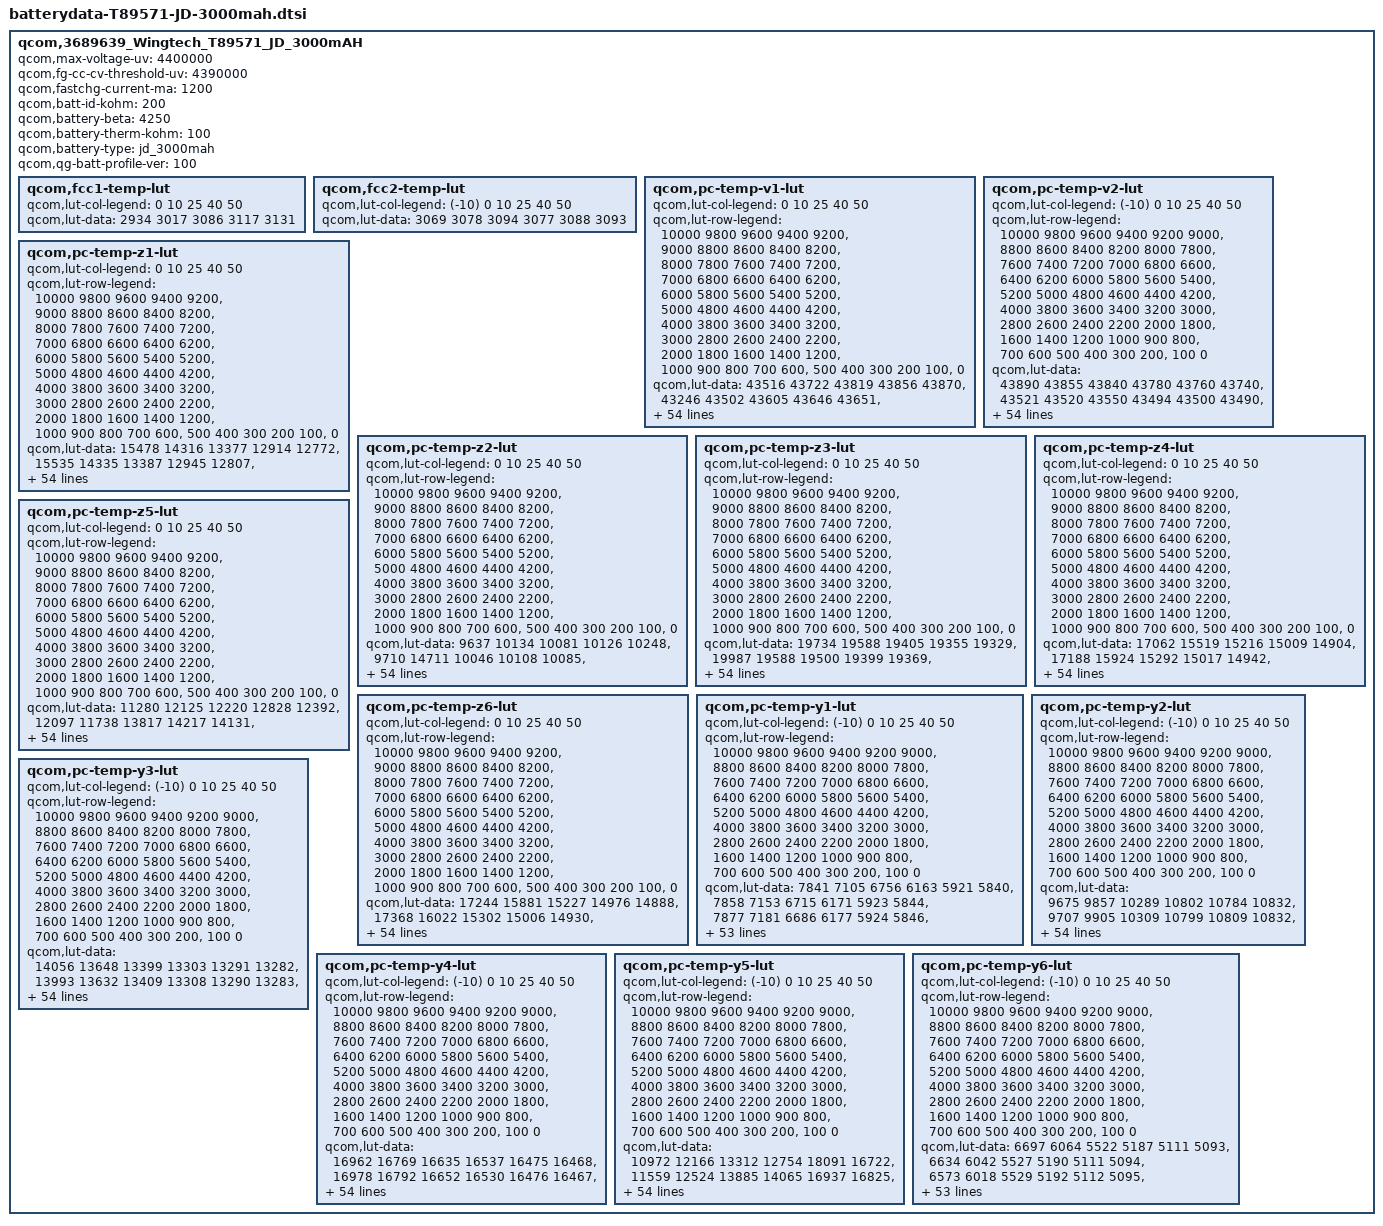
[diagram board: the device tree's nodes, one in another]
qcom,3689639_Wingtech_T89571_JD_3000mAH {
    /* 3689639_Wingtech_T89571_JD_3000mAH_averaged_MasterSlave_27thNov2018 */
    qcom,max-voltage-uv = <4400000>;
    qcom,fg-cc-cv-threshold-uv = <4390000>;
    qcom,fastchg-current-ma = <1200>; /* charging current is at 1A. */
    qcom,batt-id-kohm = <200>;
    qcom,battery-beta = <4250>;
    qcom,battery-therm-kohm = <100>;
    qcom,battery-type = "jd_3000mah";
    qcom,qg-batt-profile-ver = <100>;

	qcom,fcc1-temp-lut {
		qcom,lut-col-legend = <0 10 25 40 50>;
		qcom,lut-data = <2934 3017 3086 3117 3131>;
	};

	qcom,fcc2-temp-lut {
		qcom,lut-col-legend = <(-10) 0 10 25 40 50>;
		qcom,lut-data = <3069 3078 3094 3077 3088 3093>;
	};

	qcom,pc-temp-v1-lut {
		qcom,lut-col-legend = <0 10 25 40 50>;
		qcom,lut-row-legend = <10000 9800 9600 9400 9200>,
			<9000 8800 8600 8400 8200>,
			<8000 7800 7600 7400 7200>,
			<7000 6800 6600 6400 6200>,
			<6000 5800 5600 5400 5200>,
			<5000 4800 4600 4400 4200>,
			<4000 3800 3600 3400 3200>,
			<3000 2800 2600 2400 2200>,
			<2000 1800 1600 1400 1200>,
			<1000 900 800 700 600>,
			<500 400 300 200 100>,
			<0>;
		qcom,lut-data = <43516 43722 43819 43856 43870>,
			<43246 43502 43605 43646 43651>,
			<42996 43238 43377 43431 43442>,
			<42763 42981 43146 43205 43220>,
			<42538 42745 42913 42975 42992>,
			<42317 42515 42674 42743 42762>,
			<42101 42287 42435 42510 42531>,
			<41890 42064 42200 42277 42299>,
			<41683 41847 41971 42045 42069>,
			<41484 41635 41747 41817 41839>,
			<41302 41432 41527 41592 41613>,
			<41129 41250 41317 41372 41391>,
			<40929 41079 41129 41155 41173>,
			<40680 40877 40952 40945 40960>,
			<40428 40608 40741 40737 40751>,
			<40201 40341 40482 40532 40552>,
			<39986 40137 40250 40334 40359>,
			<39817 39963 40081 40154 40175>,
			<39693 39814 39933 39987 40000>,
			<39584 39693 39782 39821 39827>,
			<39465 39573 39634 39659 39664>,
			<39346 39431 39459 39484 39492>,
			<39228 39276 39201 39242 39272>,
			<39111 39108 38942 38971 39015>,
			<38998 38915 38781 38802 38833>,
			<38887 38739 38662 38698 38717>,
			<38776 38611 38567 38606 38617>,
			<38673 38506 38491 38511 38514>,
			<38582 38428 38423 38421 38417>,
			<38499 38367 38354 38334 38326>,
			<38431 38319 38290 38252 38242>,
			<38375 38278 38231 38180 38167>,
			<38325 38242 38177 38118 38101>,
			<38277 38208 38126 38061 38040>,
			<38234 38177 38080 38008 37982>,
			<38194 38143 38037 37959 37926>,
			<38161 38108 37995 37908 37866>,
			<38124 38069 37956 37859 37802>,
			<38072 38013 37903 37799 37729>,
			<38001 37925 37814 37712 37642>,
			<37913 37818 37703 37605 37541>,
			<37791 37698 37586 37489 37425>,
			<37652 37560 37452 37358 37290>,
			<37497 37401 37296 37204 37137>,
			<37348 37259 37153 37063 36997>,
			<37240 37172 37069 36977 36917>,
			<37202 37143 37042 36956 36896>,
			<37172 37117 37030 36940 36881>,
			<37145 37093 37012 36921 36862>,
			<37094 37048 36959 36862 36789>,
			<36881 36818 36702 36605 36511>,
			<36442 36384 36266 36171 36068>,
			<35873 35813 35697 35603 35496>,
			<35103 35036 34916 34831 34715>,
			<33880 33825 33701 33646 33512>,
			<30000 30000 30000 30000 30000>;
	};

	qcom,pc-temp-v2-lut {
		qcom,lut-col-legend = <(-10) 0 10 25 40 50>;
		qcom,lut-row-legend = <10000 9800 9600 9400 9200 9000>,
			<8800 8600 8400 8200 8000 7800>,
			<7600 7400 7200 7000 6800 6600>,
			<6400 6200 6000 5800 5600 5400>,
			<5200 5000 4800 4600 4400 4200>,
			<4000 3800 3600 3400 3200 3000>,
			<2800 2600 2400 2200 2000 1800>,
			<1600 1400 1200 1000 900 800>,
			<700 600 500 400 300 200>,
			<100 0>;
		qcom,lut-data = <43890 43855 43840 43780 43760 43740>,
			<43521 43520 43550 43494 43500 43490>,
			<43183 43209 43276 43224 43248 43247>,
			<42881 42926 43016 42973 43006 43010>,
			<42611 42668 42771 42738 42774 42780>,
			<42356 42420 42530 42507 42543 42550>,
			<42113 42178 42289 42275 42313 42319>,
			<41878 41947 42053 42046 42085 42089>,
			<41640 41740 41828 41820 41858 41862>,
			<41402 41549 41611 41597 41634 41637>,
			<41192 41351 41397 41378 41412 41415>,
			<41027 41139 41182 41159 41195 41197>,
			<40853 40930 40981 40950 40982 40982>,
			<40595 40750 40820 40765 40779 40776>,
			<40273 40579 40669 40593 40581 40575>,
			<39980 40332 40440 40395 40385 40381>,
			<39693 39925 40077 40155 40189 40192>,
			<39448 39579 39763 39935 40004 40011>,
			<39286 39414 39576 39781 39842 39844>,
			<39153 39289 39420 39643 39682 39676>,
			<39012 39141 39249 39452 39482 39475>,
			<38861 38975 39073 39192 39234 39239>,
			<38714 38818 38910 38964 39015 39027>,
			<38576 38678 38760 38796 38833 38844>,
			<38448 38546 38622 38653 38677 38684>,
			<38335 38416 38500 38529 38550 38554>,
			<38234 38289 38389 38420 38443 38444>,
			<38145 38184 38283 38319 38344 38343>,
			<38071 38098 38179 38224 38253 38250>,
			<38005 38024 38085 38136 38167 38165>,
			<37943 37963 38002 38059 38090 38086>,
			<37886 37909 37927 37989 38017 38012>,
			<37830 37861 37869 37925 37944 37944>,
			<37773 37817 37821 37866 37873 37883>,
			<37718 37773 37777 37809 37799 37813>,
			<37662 37729 37739 37747 37724 37714>,
			<37606 37682 37699 37681 37648 37603>,
			<37550 37628 37647 37617 37564 37502>,
			<37492 37564 37583 37554 37473 37406>,
			<37434 37491 37511 37485 37384 37316>,
			<37374 37406 37431 37400 37303 37237>,
			<37311 37313 37336 37299 37211 37145>,
			<37243 37221 37219 37176 37092 37025>,
			<37165 37127 37100 37045 36962 36896>,
			<37072 37032 36984 36922 36848 36786>,
			<36958 36942 36902 36871 36810 36757>,
			<36898 36900 36874 36853 36798 36746>,
			<36819 36858 36846 36836 36780 36725>,
			<36721 36792 36798 36805 36751 36690>,
			<36563 36678 36697 36714 36645 36562>,
			<36288 36423 36445 36421 36315 36196>,
			<35863 35970 35968 35926 35826 35689>,
			<35242 35328 35318 35294 35180 35033>,
			<34331 34415 34409 34447 34306 34145>,
			<32892 33070 33002 33139 33077 32828>,
			<28907 28291 28121 27780 28879 28426>;
	};

	qcom,pc-temp-z1-lut {
		qcom,lut-col-legend = <0 10 25 40 50>;
		qcom,lut-row-legend = <10000 9800 9600 9400 9200>,
			<9000 8800 8600 8400 8200>,
			<8000 7800 7600 7400 7200>,
			<7000 6800 6600 6400 6200>,
			<6000 5800 5600 5400 5200>,
			<5000 4800 4600 4400 4200>,
			<4000 3800 3600 3400 3200>,
			<3000 2800 2600 2400 2200>,
			<2000 1800 1600 1400 1200>,
			<1000 900 800 700 600>,
			<500 400 300 200 100>,
			<0>;
		qcom,lut-data = <15478 14316 13377 12914 12772>,
			<15535 14335 13387 12945 12807>,
			<15545 14317 13391 12941 12805>,
			<15528 14309 13388 12935 12804>,
			<15511 14329 13383 12925 12800>,
			<15504 14349 13375 12920 12797>,
			<15500 14341 13364 12916 12796>,
			<15498 14311 13354 12914 12797>,
			<15495 14298 13341 12914 12799>,
			<15492 14305 13338 12915 12802>,
			<15486 14312 13346 12915 12803>,
			<15475 14315 13356 12916 12804>,
			<15458 14322 13358 12918 12806>,
			<15425 14319 13358 12921 12808>,
			<15388 14272 13353 12923 12810>,
			<15362 14228 13335 12921 12813>,
			<15339 14224 13325 12920 12816>,
			<15320 14229 13331 12921 12819>,
			<15306 14237 13344 12927 12822>,
			<15296 14254 13354 12932 12824>,
			<15285 14266 13363 12937 12826>,
			<15261 14266 13370 12942 12829>,
			<15246 14268 13376 12944 12832>,
			<15243 14275 13382 12946 12836>,
			<15241 14286 13389 12949 12840>,
			<15245 14296 13397 12953 12844>,
			<15265 14298 13401 12958 12848>,
			<15288 14297 13402 12964 12854>,
			<15310 14303 13404 12970 12860>,
			<15329 14317 13409 12977 12866>,
			<15332 14328 13417 12984 12872>,
			<15298 14327 13425 12990 12877>,
			<15270 14323 13436 12994 12882>,
			<15295 14325 13443 12998 12887>,
			<15347 14335 13446 13003 12892>,
			<15367 14347 13450 13009 12897>,
			<15352 14357 13458 13015 12900>,
			<15338 14367 13473 13021 12903>,
			<15364 14381 13484 13027 12905>,
			<15419 14404 13487 13032 12909>,
			<15441 14419 13490 13037 12914>,
			<15425 14415 13494 13041 12918>,
			<15408 14409 13499 13045 12922>,
			<15381 14415 13508 13049 12923>,
			<15378 14420 13530 13056 12926>,
			<15465 14450 13544 13063 12934>,
			<15436 14428 13522 13066 12935>,
			<15402 14439 13520 13067 12935>,
			<15359 14429 13533 13066 12939>,
			<15443 14438 13542 13070 12943>,
			<15400 14448 13541 13085 12950>,
			<15417 14459 13563 13089 12958>,
			<15462 14512 13586 13104 12971>,
			<15500 14565 13613 13127 12990>,
			<15500 14565 13613 13127 12990>,
			<15500 14565 13613 13127 12990>;
	};

	qcom,pc-temp-z2-lut {
		qcom,lut-col-legend = <0 10 25 40 50>;
		qcom,lut-row-legend = <10000 9800 9600 9400 9200>,
			<9000 8800 8600 8400 8200>,
			<8000 7800 7600 7400 7200>,
			<7000 6800 6600 6400 6200>,
			<6000 5800 5600 5400 5200>,
			<5000 4800 4600 4400 4200>,
			<4000 3800 3600 3400 3200>,
			<3000 2800 2600 2400 2200>,
			<2000 1800 1600 1400 1200>,
			<1000 900 800 700 600>,
			<500 400 300 200 100>,
			<0>;
		qcom,lut-data = <9637 10134 10081 10126 10248>,
			<9710 14711 10046 10108 10085>,
			<9742 11438 10101 10220 10135>,
			<9759 9866 10314 10230 10216>,
			<9765 9852 10442 10233 10245>,
			<9757 9844 10270 10220 10240>,
			<9744 9834 10033 10178 10187>,
			<9737 9824 9986 10143 10147>,
			<9733 9816 9972 10117 10139>,
			<9729 9810 9971 10097 10134>,
			<9722 9805 10059 10081 10125>,
			<9714 9802 10151 10069 10099>,
			<9704 9798 10218 10074 10083>,
			<9686 9793 10334 10106 10056>,
			<9668 9787 10390 10134 10041>,
			<9659 9782 10480 10151 10058>,
			<9652 9786 10540 10163 10084>,
			<9649 9798 10363 10144 10105>,
			<9649 9810 10091 10080 10121>,
			<9652 9827 10048 10056 10133>,
			<9657 9841 10059 10088 10142>,
			<9664 9847 10068 10123 10149>,
			<9669 9853 10068 10138 10147>,
			<9673 9861 10063 10155 10131>,
			<9677 9877 10060 10148 10129>,
			<9681 9887 10056 10103 10160>,
			<9684 9888 10058 10083 10193>,
			<9687 9890 10067 10130 10211>,
			<9695 9892 10075 10194 10224>,
			<9705 9896 10083 10214 10215>,
			<9712 9900 10095 10213 10156>,
			<9719 9902 10097 10206 10115>,
			<9726 9904 10095 10191 10086>,
			<9734 9907 10093 10178 10063>,
			<9744 9914 10095 10183 10072>,
			<9748 9921 10100 10200 10105>,
			<9729 9929 10106 10219 10152>,
			<9708 9938 10114 10240 10238>,
			<9685 9948 10124 10262 10292>,
			<9630 9959 10139 10293 10287>,
			<9611 9969 10154 10320 10277>,
			<9616 9977 10163 10322 10263>,
			<9618 9986 10170 10317 10237>,
			<9513 10000 10174 10293 10273>,
			<9545 10094 10201 10260 10316>,
			<9535 10045 10257 10255 10264>,
			<9544 10099 10243 10256 10285>,
			<9504 10108 10254 10252 10268>,
			<9494 10127 10371 10271 10315>,
			<9536 9993 10348 10375 10348>,
			<9487 9960 10329 10342 10218>,
			<9438 10007 10310 10271 10108>,
			<9435 9849 10372 10192 10030>,
			<9334 9852 10319 10130 9988>,
			<9334 9852 10319 10130 9988>,
			<9334 9852 10319 10130 9988>;
	};

	qcom,pc-temp-z3-lut {
		qcom,lut-col-legend = <0 10 25 40 50>;
		qcom,lut-row-legend = <10000 9800 9600 9400 9200>,
			<9000 8800 8600 8400 8200>,
			<8000 7800 7600 7400 7200>,
			<7000 6800 6600 6400 6200>,
			<6000 5800 5600 5400 5200>,
			<5000 4800 4600 4400 4200>,
			<4000 3800 3600 3400 3200>,
			<3000 2800 2600 2400 2200>,
			<2000 1800 1600 1400 1200>,
			<1000 900 800 700 600>,
			<500 400 300 200 100>,
			<0>;
		qcom,lut-data = <19734 19588 19405 19355 19329>,
			<19987 19588 19500 19399 19369>,
			<20050 19744 19553 19447 19398>,
			<20054 19814 19577 19466 19430>,
			<20047 19824 19589 19475 19447>,
			<20031 19829 19594 19478 19450>,
			<20013 19827 19596 19480 19450>,
			<20008 19819 19593 19480 19450>,
			<20012 19808 19589 19477 19447>,
			<20014 19793 19585 19472 19442>,
			<20008 19778 19589 19458 19434>,
			<19996 19765 19595 19438 19420>,
			<19995 19753 19597 19431 19411>,
			<20040 19750 19596 19429 19405>,
			<20085 19766 19593 19429 19399>,
			<20085 19781 19588 19427 19391>,
			<20075 19771 19580 19424 19381>,
			<20062 19741 19548 19416 19377>,
			<20027 19711 19506 19401 19374>,
			<19985 19676 19496 19395 19372>,
			<19960 19653 19494 19397 19370>,
			<19942 19664 19494 19401 19369>,
			<19933 19697 19512 19407 19369>,
			<19933 19722 19533 19416 19370>,
			<19938 19742 19532 19415 19368>,
			<19946 19754 19524 19396 19356>,
			<19968 19753 19517 19384 19348>,
			<19985 19751 19510 19389 19361>,
			<19989 19747 19505 19398 19387>,
			<19988 19740 19508 19412 19399>,
			<19980 19730 19513 19437 19409>,
			<19961 19719 19518 19447 19411>,
			<19940 19707 19523 19442 19405>,
			<19924 19695 19526 19434 19395>,
			<19908 19684 19524 19426 19386>,
			<19876 19673 19520 19418 19376>,
			<19758 19662 19515 19412 19374>,
			<19639 19651 19508 19408 19376>,
			<19575 19647 19501 19405 19377>,
			<19484 19647 19496 19404 19375>,
			<19449 19646 19492 19403 19371>,
			<19451 19640 19489 19401 19370>,
			<19449 19630 19486 19396 19371>,
			<19384 19616 19482 19392 19372>,
			<19349 19572 19471 19386 19372>,
			<19326 19389 19445 19375 19356>,
			<19323 19347 19442 19369 19350>,
			<19323 19332 19397 19366 19347>,
			<19320 19324 19359 19364 19335>,
			<19317 19299 19377 19349 19338>,
			<19321 19312 19388 19359 19359>,
			<19332 19308 19397 19361 19372>,
			<19342 19311 19358 19375 19374>,
			<19353 19348 19343 19370 19379>,
			<19353 19348 19343 19370 19379>,
			<19353 19348 19343 19370 19379>;
	};

	qcom,pc-temp-z4-lut {
		qcom,lut-col-legend = <0 10 25 40 50>;
		qcom,lut-row-legend = <10000 9800 9600 9400 9200>,
			<9000 8800 8600 8400 8200>,
			<8000 7800 7600 7400 7200>,
			<7000 6800 6600 6400 6200>,
			<6000 5800 5600 5400 5200>,
			<5000 4800 4600 4400 4200>,
			<4000 3800 3600 3400 3200>,
			<3000 2800 2600 2400 2200>,
			<2000 1800 1600 1400 1200>,
			<1000 900 800 700 600>,
			<500 400 300 200 100>,
			<0>;
		qcom,lut-data = <17062 15519 15216 15009 14904>,
			<17188 15924 15292 15017 14942>,
			<17137 15875 15406 15105 14987>,
			<16824 15809 15260 15064 14989>,
			<16495 15651 15135 14997 14940>,
			<16279 15466 15069 14951 14903>,
			<16091 15348 15016 14913 14873>,
			<15933 15255 14969 14879 14846>,
			<15796 15184 14926 14845 14816>,
			<15680 15132 14883 14819 14791>,
			<15584 15086 14831 14809 14781>,
			<15501 15037 14783 14802 14775>,
			<15427 14989 14745 14791 14769>,
			<15355 14948 14707 14774 14760>,
			<15293 14910 14699 14757 14750>,
			<15250 14882 14702 14745 14742>,
			<15216 14871 14707 14735 14735>,
			<15184 14864 14722 14728 14726>,
			<15151 14863 14740 14723 14714>,
			<15123 14858 14742 14721 14708>,
			<15101 14850 14737 14721 14711>,
			<15081 14831 14735 14722 14717>,
			<15059 14799 14812 14781 14766>,
			<15031 14793 14909 14902 14881>,
			<15002 14834 14932 14931 14919>,
			<14977 14876 14939 14927 14916>,
			<14953 14891 14934 14921 14908>,
			<14935 14903 14913 14898 14877>,
			<14923 14900 14884 14860 14824>,
			<14913 14884 14856 14820 14786>,
			<14909 14865 14825 14771 14753>,
			<14906 14849 14798 14743 14734>,
			<14902 14832 14773 14729 14722>,
			<14895 14818 14756 14721 14715>,
			<14887 14804 14747 14722 14716>,
			<14892 14793 14741 14725 14721>,
			<14996 14784 14738 14728 14726>,
			<15098 14776 14737 14732 14733>,
			<15137 14770 14737 14736 14739>,
			<15212 14764 14748 14745 14745>,
			<15235 14761 14761 14755 14750>,
			<15213 14758 14756 14753 14749>,
			<15196 14757 14745 14746 14740>,
			<15223 14756 14743 14748 14740>,
			<15139 14755 14734 14747 14739>,
			<15103 14887 14701 14711 14708>,
			<15100 14921 14689 14699 14696>,
			<15094 14929 14722 14676 14672>,
			<15088 14930 14749 14657 14659>,
			<15079 14947 14726 14675 14661>,
			<15076 14947 14746 14705 14680>,
			<15098 14969 14750 14715 14678>,
			<15110 14980 14798 14703 14680>,
			<15122 14964 14825 14712 14677>,
			<15122 14964 14825 14712 14677>,
			<15122 14964 14825 14712 14677>;
	};

	qcom,pc-temp-z5-lut {
		qcom,lut-col-legend = <0 10 25 40 50>;
		qcom,lut-row-legend = <10000 9800 9600 9400 9200>,
			<9000 8800 8600 8400 8200>,
			<8000 7800 7600 7400 7200>,
			<7000 6800 6600 6400 6200>,
			<6000 5800 5600 5400 5200>,
			<5000 4800 4600 4400 4200>,
			<4000 3800 3600 3400 3200>,
			<3000 2800 2600 2400 2200>,
			<2000 1800 1600 1400 1200>,
			<1000 900 800 700 600>,
			<500 400 300 200 100>,
			<0>;
		qcom,lut-data = <11280 12125 12220 12828 12392>,
			<12097 11738 13817 14217 14131>,
			<12535 12771 14025 14939 14837>,
			<12797 13464 14273 15237 15688>,
			<12992 13758 14487 15575 16407>,
			<13144 13972 14908 15816 16687>,
			<13282 14177 15480 16012 16765>,
			<13450 14387 15868 16261 16883>,
			<13699 14502 16196 16685 17372>,
			<13878 14540 16708 16972 17880>,
			<13914 14571 18543 16706 17799>,
			<13932 14678 20418 16156 17317>,
			<14024 14968 22184 16122 17074>,
			<14720 15496 24684 16815 17262>,
			<15487 17415 25191 17632 17446>,
			<15792 19103 25545 18506 17343>,
			<15990 18843 25481 19213 17227>,
			<16000 17850 23019 19105 17364>,
			<15585 17107 19799 18560 18208>,
			<15089 16431 19438 18423 19036>,
			<14979 15997 20472 19858 19630>,
			<15044 17644 22332 21583 20118>,
			<15214 22545 30088 23072 20284>,
			<15636 27672 37846 24815 19892>,
			<16329 34651 36414 24185 18907>,
			<17506 39339 29997 19522 16177>,
			<20218 38643 25349 16266 14326>,
			<22266 36416 22177 15738 14633>,
			<23134 34270 20469 15578 15443>,
			<23970 32104 20532 16507 16482>,
			<24001 29999 20881 19643 18472>,
			<22926 28069 21629 22471 20246>,
			<21682 26292 24109 24821 21735>,
			<21022 25087 26888 26542 22798>,
			<20484 24220 29570 27324 23020>,
			<19475 23586 31797 27837 23060>,
			<16672 23036 31883 27820 23232>,
			<14041 22562 30752 26849 23794>,
			<12942 22753 29478 25551 24175>,
			<11678 24891 27868 23954 22595>,
			<11236 26501 26387 22231 20001>,
			<11298 25608 25801 21165 19384>,
			<11349 24385 25334 20374 19331>,
			<11161 23561 24286 19302 19073>,
			<11267 21185 24114 18761 18634>,
			<11167 12582 23130 19152 18085>,
			<11134 11765 22773 18567 17722>,
			<11119 11547 16052 19407 19027>,
			<11088 11456 13395 21028 19149>,
			<11102 11276 14531 17433 18677>,
			<11189 11526 14760 15411 17254>,
			<11232 11406 14655 14587 17796>,
			<11235 11341 12687 15364 17242>,
			<11182 11472 12097 14511 17144>,
			<11182 11472 12097 14511 17144>,
			<11182 11472 12097 14511 17144>;
	};

	qcom,pc-temp-z6-lut {
		qcom,lut-col-legend = <0 10 25 40 50>;
		qcom,lut-row-legend = <10000 9800 9600 9400 9200>,
			<9000 8800 8600 8400 8200>,
			<8000 7800 7600 7400 7200>,
			<7000 6800 6600 6400 6200>,
			<6000 5800 5600 5400 5200>,
			<5000 4800 4600 4400 4200>,
			<4000 3800 3600 3400 3200>,
			<3000 2800 2600 2400 2200>,
			<2000 1800 1600 1400 1200>,
			<1000 900 800 700 600>,
			<500 400 300 200 100>,
			<0>;
		qcom,lut-data = <17244 15881 15227 14976 14888>,
			<17368 16022 15302 15006 14930>,
			<17347 16037 15368 15067 14966>,
			<17170 16036 15315 15055 14977>,
			<16980 15960 15265 15034 14968>,
			<16849 15852 15233 15017 14959>,
			<16734 15782 15206 15001 14947>,
			<16642 15725 15181 14985 14934>,
			<16566 15677 15157 14969 14921>,
			<16501 15639 15135 14955 14908>,
			<16441 15606 15116 14942 14898>,
			<16387 15571 15098 14929 14889>,
			<16344 15537 15082 14919 14880>,
			<16310 15510 15067 14912 14873>,
			<16279 15489 15059 14904 14865>,
			<16247 15472 15054 14898 14858>,
			<16215 15456 15049 14891 14850>,
			<16182 15441 15037 14883 14844>,
			<16144 15428 15026 14874 14837>,
			<16107 15411 15023 14870 14834>,
			<16080 15401 15022 14872 14834>,
			<16058 15403 15023 14874 14836>,
			<16042 15411 15067 14904 14857>,
			<16028 15423 15120 14962 14908>,
			<16018 15452 15130 14974 14925>,
			<16018 15479 15131 14966 14920>,
			<16025 15488 15128 14956 14913>,
			<16031 15495 15117 14948 14906>,
			<16031 15494 15105 14939 14899>,
			<16030 15485 15095 14932 14891>,
			<16028 15474 15087 14926 14884>,
			<16020 15465 15080 14919 14876>,
			<16011 15455 15075 14911 14868>,
			<16004 15447 15070 14905 14861>,
			<15998 15439 15067 14901 14857>,
			<15989 15432 15064 14899 14854>,
			<15978 15428 15062 14898 14854>,
			<15967 15424 15060 14898 14858>,
			<15961 15424 15060 14898 14861>,
			<15956 15427 15065 14901 14863>,
			<15952 15431 15070 14906 14864>,
			<15952 15432 15070 14905 14864>,
			<15951 15433 15067 14901 14861>,
			<15943 15433 15067 14901 14862>,
			<15899 15415 15062 14899 14862>,
			<15876 15389 15038 14878 14841>,
			<15873 15383 15033 14870 14833>,
			<15873 15380 15023 14859 14821>,
			<15871 15379 15018 14850 14809>,
			<15875 15381 15021 14852 14812>,
			<15888 15395 15039 14871 14833>,
			<15915 15414 15050 14879 14842>,
			<15945 15436 15059 14885 14847>,
			<15987 15468 15072 14892 14852>,
			<15987 15468 15072 14892 14852>,
			<15987 15468 15072 14892 14852>;
	};

	qcom,pc-temp-y1-lut {
		qcom,lut-col-legend = <(-10) 0 10 25 40 50>;
		qcom,lut-row-legend = <10000 9800 9600 9400 9200 9000>,
			<8800 8600 8400 8200 8000 7800>,
			<7600 7400 7200 7000 6800 6600>,
			<6400 6200 6000 5800 5600 5400>,
			<5200 5000 4800 4600 4400 4200>,
			<4000 3800 3600 3400 3200 3000>,
			<2800 2600 2400 2200 2000 1800>,
			<1600 1400 1200 1000 900 800>,
			<700 600 500 400 300 200>,
			<100 0>;
		qcom,lut-data = <7841 7105 6756 6163 5921 5840>,
			<7858 7153 6715 6171 5923 5844>,
			<7877 7181 6686 6177 5924 5846>,
			<7894 7194 6668 6180 5924 5846>,
			<7906 7198 6658 6182 5924 5846>,
			<7910 7198 6656 6182 5923 5845>,
			<7907 7182 6669 6179 5921 5842>,
			<7901 7163 6683 6174 5918 5838>,
			<7896 7158 6677 6173 5917 5838>,
			<7885 7151 6656 6173 5917 5838>,
			<7883 7149 6647 6173 5917 5839>,
			<7898 7164 6648 6170 5916 5838>,
			<7910 7181 6649 6167 5916 5838>,
			<7898 7188 6648 6167 5915 5837>,
			<7876 7193 6647 6168 5914 5837>,
			<7871 7198 6651 6172 5914 5837>,
			<7882 7206 6674 6184 5915 5838>,
			<7894 7211 6690 6194 5917 5840>,
			<7902 7206 6686 6195 5918 5841>,
			<7910 7196 6680 6195 5918 5842>,
			<7907 7196 6676 6195 5919 5843>,
			<7892 7207 6673 6195 5921 5844>,
			<7885 7214 6672 6195 5923 5846>,
			<7890 7217 6669 6196 5925 5849>,
			<7896 7220 6666 6197 5927 5851>,
			<7893 7212 6668 6201 5930 5854>,
			<7880 7192 6673 6209 5934 5855>,
			<7871 7184 6677 6213 5938 5857>,
			<7871 7195 6682 6212 5941 5860>,
			<7872 7205 6685 6211 5944 5863>,
			<7880 7198 6681 6213 5947 5867>,
			<7895 7178 6674 6218 5951 5871>,
			<7895 7172 6673 6221 5955 5874>,
			<7885 7175 6674 6223 5960 5877>,
			<7876 7179 6676 6224 5965 5879>,
			<7862 7188 6682 6227 5968 5882>,
			<7842 7201 6691 6231 5970 5884>,
			<7828 7201 6696 6234 5972 5887>,
			<7820 7177 6699 6239 5973 5889>,
			<7823 7161 6700 6244 5975 5890>,
			<7881 7173 6688 6249 5977 5892>,
			<7934 7188 6682 6254 5979 5894>,
			<7869 7220 6689 6258 5982 5897>,
			<7866 7223 6713 6262 5987 5902>,
			<7977 7252 6732 6279 5993 5906>,
			<7923 7249 6742 6275 5999 5910>,
			<7944 7246 6752 6279 6005 5911>,
			<7951 7245 6726 6285 6002 5911>,
			<7958 7264 6741 6294 6003 5914>,
			<7977 7276 6725 6295 6002 5913>,
			<7990 7288 6736 6290 6004 5916>,
			<8021 7287 6754 6311 6015 5924>,
			<8046 7299 6760 6338 6028 5932>,
			<8189 7348 6799 6346 6048 5946>,
			<8189 7348 6799 6346 6048 5946>,
			<8189 7348 6799 6346 6048 5946>;
	};

	qcom,pc-temp-y2-lut {
		qcom,lut-col-legend = <(-10) 0 10 25 40 50>;
		qcom,lut-row-legend = <10000 9800 9600 9400 9200 9000>,
			<8800 8600 8400 8200 8000 7800>,
			<7600 7400 7200 7000 6800 6600>,
			<6400 6200 6000 5800 5600 5400>,
			<5200 5000 4800 4600 4400 4200>,
			<4000 3800 3600 3400 3200 3000>,
			<2800 2600 2400 2200 2000 1800>,
			<1600 1400 1200 1000 900 800>,
			<700 600 500 400 300 200>,
			<100 0>;
		qcom,lut-data = <9675 9857 10289 10802 10784 10832>,
			<9707 9905 10309 10799 10809 10832>,
			<9742 9951 10329 10788 10821 10817>,
			<9776 9994 10348 10772 10825 10794>,
			<9805 10032 10364 10756 10822 10768>,
			<9826 10063 10375 10740 10816 10745>,
			<9839 10088 10383 10719 10797 10712>,
			<9851 10111 10388 10700 10775 10686>,
			<9878 10138 10394 10697 10765 10691>,
			<9929 10174 10402 10700 10755 10713>,
			<9977 10216 10411 10705 10752 10731>,
			<10026 10349 10446 10717 10767 10756>,
			<10059 10468 10481 10733 10786 10784>,
			<10058 10473 10531 10752 10808 10808>,
			<10055 10458 10613 10776 10852 10834>,
			<10052 10452 10635 10796 10916 10875>,
			<10053 10451 10617 10815 11056 10946>,
			<10057 10453 10608 10838 11139 11020>,
			<10071 10484 10622 10884 11128 11098>,
			<10093 10535 10640 10935 11105 11161>,
			<10098 10559 10658 10934 11075 11150>,
			<10093 10576 10677 10889 11031 11075>,
			<10087 10583 10693 10863 10999 11019>,
			<10083 10580 10708 10867 10963 10981>,
			<10079 10575 10719 10874 10935 10956>,
			<10035 10498 10722 10884 10952 10962>,
			<9825 10273 10724 10899 11004 10992>,
			<9688 10177 10725 10913 11023 11033>,
			<9679 10172 10727 10928 11037 11108>,
			<9674 10170 10726 10939 11058 11160>,
			<9672 10162 10719 10944 11100 11148>,
			<9671 10148 10710 10949 11157 11123>,
			<9670 10138 10704 10949 11167 11143>,
			<9669 10131 10698 10945 11147 11284>,
			<9667 10123 10691 10940 11128 11368>,
			<9666 10112 10680 10932 11120 11250>,
			<9664 10098 10664 10921 11113 11077>,
			<9663 10048 10590 10911 11089 11010>,
			<9662 9830 10407 10901 11032 10973>,
			<9661 9676 10296 10888 10991 10957>,
			<9661 9670 10247 10874 10987 10973>,
			<9660 9666 10204 10855 10989 10971>,
			<9660 9665 10156 10820 10961 10940>,
			<9659 9663 10124 10791 10915 10936>,
			<9659 9663 10115 10732 10904 10861>,
			<9658 9661 10071 10741 10839 10733>,
			<9658 9660 10058 10717 10819 10743>,
			<9657 9659 10052 10712 10825 10745>,
			<9657 9658 10042 10731 10851 10796>,
			<9656 9658 10041 10742 10852 10772>,
			<9656 9657 10003 10702 10784 10723>,
			<9656 9657 9721 10629 10765 10628>,
			<9655 9656 9679 10563 10709 10614>,
			<9653 9655 9666 10527 10653 10549>,
			<9653 9655 9666 10527 10653 10549>,
			<9653 9655 9666 10527 10653 10549>;
	};

	qcom,pc-temp-y3-lut {
		qcom,lut-col-legend = <(-10) 0 10 25 40 50>;
		qcom,lut-row-legend = <10000 9800 9600 9400 9200 9000>,
			<8800 8600 8400 8200 8000 7800>,
			<7600 7400 7200 7000 6800 6600>,
			<6400 6200 6000 5800 5600 5400>,
			<5200 5000 4800 4600 4400 4200>,
			<4000 3800 3600 3400 3200 3000>,
			<2800 2600 2400 2200 2000 1800>,
			<1600 1400 1200 1000 900 800>,
			<700 600 500 400 300 200>,
			<100 0>;
		qcom,lut-data = <14056 13648 13399 13303 13291 13282>,
			<13993 13632 13409 13308 13290 13283>,
			<13932 13616 13417 13314 13290 13285>,
			<13875 13601 13424 13319 13291 13287>,
			<13823 13587 13429 13323 13293 13288>,
			<13777 13576 13430 13326 13295 13290>,
			<13733 13562 13429 13328 13297 13291>,
			<13698 13551 13427 13329 13300 13293>,
			<13678 13552 13425 13330 13302 13294>,
			<13667 13562 13424 13330 13303 13296>,
			<13656 13564 13423 13331 13305 13297>,
			<13609 13537 13426 13331 13307 13298>,
			<13561 13508 13427 13332 13310 13299>,
			<13558 13493 13423 13332 13313 13301>,
			<13563 13478 13415 13332 13317 13305>,
			<13560 13465 13410 13332 13317 13308>,
			<13536 13448 13401 13332 13315 13310>,
			<13514 13436 13394 13332 13312 13312>,
			<13514 13434 13389 13334 13308 13307>,
			<13518 13433 13385 13336 13304 13300>,
			<13519 13429 13380 13335 13301 13295>,
			<13515 13420 13375 13327 13299 13291>,
			<13510 13413 13370 13320 13296 13288>,
			<13507 13409 13365 13316 13292 13285>,
			<13504 13405 13361 13314 13288 13283>,
			<13502 13402 13360 13314 13289 13283>,
			<13502 13397 13359 13314 13290 13283>,
			<13503 13394 13358 13314 13291 13283>,
			<13510 13392 13356 13313 13291 13284>,
			<13521 13391 13354 13312 13291 13284>,
			<13535 13391 13351 13313 13292 13284>,
			<13553 13392 13347 13313 13295 13283>,
			<13569 13394 13347 13315 13295 13283>,
			<13583 13406 13350 13316 13293 13287>,
			<13598 13420 13353 13318 13292 13290>,
			<13619 13429 13357 13317 13292 13288>,
			<13645 13438 13361 13316 13293 13285>,
			<13677 13452 13362 13315 13293 13284>,
			<13717 13475 13362 13316 13291 13283>,
			<13758 13496 13363 13316 13290 13283>,
			<13797 13510 13370 13316 13291 13286>,
			<13838 13526 13378 13316 13291 13288>,
			<13889 13554 13386 13315 13292 13286>,
			<13932 13587 13389 13313 13288 13284>,
			<13875 13545 13371 13308 13289 13283>,
			<13953 13619 13384 13315 13294 13292>,
			<14012 13656 13397 13317 13299 13296>,
			<14059 13703 13418 13324 13303 13297>,
			<14121 13743 13429 13331 13310 13302>,
			<14174 13787 13441 13335 13309 13300>,
			<14232 13825 13442 13328 13299 13293>,
			<14307 13884 13463 13329 13304 13295>,
			<14445 13976 13520 13342 13308 13303>,
			<14865 14083 13600 13356 13316 13309>,
			<14865 14083 13600 13356 13316 13309>,
			<14865 14083 13600 13356 13316 13309>;
	};

	qcom,pc-temp-y4-lut {
		qcom,lut-col-legend = <(-10) 0 10 25 40 50>;
		qcom,lut-row-legend = <10000 9800 9600 9400 9200 9000>,
			<8800 8600 8400 8200 8000 7800>,
			<7600 7400 7200 7000 6800 6600>,
			<6400 6200 6000 5800 5600 5400>,
			<5200 5000 4800 4600 4400 4200>,
			<4000 3800 3600 3400 3200 3000>,
			<2800 2600 2400 2200 2000 1800>,
			<1600 1400 1200 1000 900 800>,
			<700 600 500 400 300 200>,
			<100 0>;
		qcom,lut-data = <16962 16769 16635 16537 16475 16468>,
			<16978 16792 16652 16530 16476 16467>,
			<17001 16823 16670 16526 16477 16466>,
			<17025 16854 16688 16525 16478 16466>,
			<17044 16878 16702 16525 16479 16466>,
			<17051 16891 16712 16527 16480 16466>,
			<17050 16896 16717 16530 16481 16468>,
			<17048 16898 16723 16535 16483 16470>,
			<17033 16890 16734 16541 16486 16473>,
			<16983 16873 16750 16551 16492 16477>,
			<16968 16869 16758 16561 16497 16481>,
			<17099 16914 16758 16571 16503 16488>,
			<17234 16970 16760 16584 16509 16495>,
			<17181 17014 16814 16614 16515 16499>,
			<17025 17058 16908 16654 16524 16504>,
			<16931 17044 16905 16665 16537 16510>,
			<16871 16841 16762 16664 16557 16519>,
			<16833 16690 16668 16663 16581 16532>,
			<16825 16697 16663 16669 16614 16568>,
			<16821 16712 16660 16678 16645 16606>,
			<16812 16711 16648 16660 16634 16600>,
			<16794 16689 16623 16579 16567 16555>,
			<16779 16667 16603 16524 16518 16517>,
			<16764 16647 16591 16509 16494 16490>,
			<16749 16630 16582 16501 16480 16473>,
			<16753 16624 16575 16500 16480 16474>,
			<16787 16626 16570 16503 16484 16479>,
			<16809 16629 16563 16506 16489 16486>,
			<16810 16634 16553 16512 16501 16496>,
			<16811 16640 16546 16519 16514 16508>,
			<16809 16651 16545 16527 16524 16523>,
			<16805 16665 16547 16535 16532 16540>,
			<16807 16669 16551 16540 16537 16548>,
			<16813 16666 16555 16545 16542 16553>,
			<16820 16664 16561 16547 16544 16555>,
			<16826 16667 16570 16543 16537 16538>,
			<16833 16675 16581 16536 16524 16512>,
			<16839 16682 16596 16534 16511 16498>,
			<16845 16701 16616 16534 16497 16487>,
			<16853 16715 16625 16533 16492 16484>,
			<16868 16715 16628 16532 16497 16487>,
			<16885 16712 16627 16530 16500 16489>,
			<16902 16706 16615 16524 16493 16484>,
			<16902 16704 16602 16516 16484 16473>,
			<16812 16687 16585 16491 16457 16452>,
			<16811 16697 16603 16501 16472 16465>,
			<16822 16710 16619 16523 16488 16485>,
			<16835 16731 16638 16545 16511 16512>,
			<16851 16760 16673 16573 16537 16538>,
			<16850 16780 16705 16588 16535 16532>,
			<16842 16768 16702 16552 16487 16474>,
			<16834 16740 16682 16536 16477 16473>,
			<16861 16744 16694 16551 16485 16478>,
			<17091 16780 16725 16595 16528 16526>,
			<17091 16780 16725 16595 16528 16526>,
			<17091 16780 16725 16595 16528 16526>;
	};

	qcom,pc-temp-y5-lut {
		qcom,lut-col-legend = <(-10) 0 10 25 40 50>;
		qcom,lut-row-legend = <10000 9800 9600 9400 9200 9000>,
			<8800 8600 8400 8200 8000 7800>,
			<7600 7400 7200 7000 6800 6600>,
			<6400 6200 6000 5800 5600 5400>,
			<5200 5000 4800 4600 4400 4200>,
			<4000 3800 3600 3400 3200 3000>,
			<2800 2600 2400 2200 2000 1800>,
			<1600 1400 1200 1000 900 800>,
			<700 600 500 400 300 200>,
			<100 0>;
		qcom,lut-data = <10972 12166 13312 12754 18091 16722>,
			<11559 12524 13885 14065 16937 16825>,
			<12252 13043 14562 15206 16206 16884>,
			<12942 13608 15203 16099 15799 16909>,
			<13516 14102 15666 16668 15618 16911>,
			<13864 14412 15812 16834 15570 16895>,
			<14055 14583 15708 16584 15850 16743>,
			<14194 14793 15563 16138 16128 16487>,
			<14665 15882 15504 15632 15911 16209>,
			<15993 18449 15498 14995 15470 15854>,
			<16554 19279 15539 14576 15174 15451>,
			<15519 17125 15962 14273 15075 14881>,
			<14397 15101 16338 14066 15061 14516>,
			<15558 17043 16685 13925 15092 14710>,
			<18688 21406 17446 13729 15141 15095>,
			<19517 22228 18406 13828 15038 15179>,
			<16343 19260 20731 15326 14517 15138>,
			<13582 17063 22083 17368 14180 15068>,
			<14135 17746 21411 20155 14589 14652>,
			<15460 18965 20449 23035 15500 14127>,
			<15831 19341 20303 23402 16951 14762>,
			<15706 19342 20404 22695 19581 17406>,
			<15567 19326 20384 21817 20697 18619>,
			<15359 19751 20019 20558 18865 18064>,
			<15077 20236 19637 19341 16798 17234>,
			<14634 19468 19919 19146 16699 16472>,
			<13133 16990 20808 19337 16919 15600>,
			<12223 15721 21006 19341 16960 15261>,
			<12203 14676 20404 18834 16779 15167>,
			<12193 13633 19636 18361 16635 15108>,
			<12246 13319 18542 18563 17195 14991>,
			<12380 13101 17303 19320 18301 14837>,
			<12399 13103 17158 20238 18480 15217>,
			<12341 13714 17653 21689 17960 17381>,
			<12281 14450 18278 22671 17618 18672>,
			<12258 15070 19158 22054 18600 18573>,
			<12271 15699 19923 20726 20023 18351>,
			<12339 15813 19555 20063 19912 17859>,
			<12494 15116 18114 19789 18559 16949>,
			<12644 14361 17365 19463 17466 16631>,
			<12726 13824 17220 18689 16810 17257>,
			<12806 13472 17038 17905 16613 17445>,
			<12970 13405 16528 17217 17015 17157>,
			<13156 13227 15742 16833 16003 16589>,
			<13345 12896 14299 16938 18058 16791>,
			<13617 13139 14032 16705 16124 16996>,
			<13977 13305 14520 15704 16147 16583>,
			<14030 13628 15252 16031 15740 15254>,
			<14381 13795 15425 16432 16644 15815>,
			<14599 14334 15912 16947 16872 15729>,
			<14223 14329 15720 16627 16440 16487>,
			<14115 14070 14224 17143 19515 17192>,
			<13612 13894 14078 19449 20300 21831>,
			<12460 14161 14380 22629 24353 25656>,
			<12460 14161 14380 22629 24353 25656>,
			<12460 14161 14380 22629 24353 25656>;
	};

	qcom,pc-temp-y6-lut {
		qcom,lut-col-legend = <(-10) 0 10 25 40 50>;
		qcom,lut-row-legend = <10000 9800 9600 9400 9200 9000>,
			<8800 8600 8400 8200 8000 7800>,
			<7600 7400 7200 7000 6800 6600>,
			<6400 6200 6000 5800 5600 5400>,
			<5200 5000 4800 4600 4400 4200>,
			<4000 3800 3600 3400 3200 3000>,
			<2800 2600 2400 2200 2000 1800>,
			<1600 1400 1200 1000 900 800>,
			<700 600 500 400 300 200>,
			<100 0>;
		qcom,lut-data = <6697 6064 5522 5187 5111 5093>,
			<6634 6042 5527 5190 5111 5094>,
			<6573 6018 5529 5192 5112 5095>,
			<6516 5995 5529 5195 5113 5096>,
			<6462 5972 5527 5197 5114 5098>,
			<6413 5950 5523 5199 5116 5099>,
			<6368 5927 5517 5200 5118 5100>,
			<6326 5907 5509 5202 5120 5102>,
			<6289 5893 5506 5203 5122 5104>,
			<6255 5882 5503 5205 5125 5106>,
			<6238 5871 5500 5208 5127 5108>,
			<6234 5855 5495 5210 5130 5111>,
			<6230 5843 5492 5214 5134 5114>,
			<6210 5842 5501 5221 5138 5117>,
			<6173 5842 5518 5231 5142 5120>,
			<6149 5833 5515 5235 5147 5124>,
			<6127 5774 5472 5236 5151 5128>,
			<6112 5730 5441 5237 5156 5133>,
			<6114 5733 5436 5240 5162 5139>,
			<6120 5737 5432 5243 5167 5145>,
			<6120 5737 5425 5237 5163 5141>,
			<6116 5728 5414 5208 5142 5125>,
			<6112 5719 5407 5188 5125 5111>,
			<6110 5714 5402 5182 5115 5101>,
			<6109 5711 5400 5179 5109 5095>,
			<6111 5709 5400 5179 5110 5095>,
			<6116 5708 5401 5181 5112 5097>,
			<6123 5708 5402 5183 5115 5099>,
			<6132 5713 5403 5186 5119 5103>,
			<6145 5723 5404 5188 5123 5107>,
			<6159 5733 5406 5192 5127 5111>,
			<6176 5747 5412 5196 5132 5115>,
			<6195 5763 5418 5200 5133 5120>,
			<6215 5782 5429 5205 5134 5124>,
			<6238 5803 5442 5207 5134 5126>,
			<6262 5826 5456 5208 5133 5120>,
			<6290 5852 5471 5207 5130 5110>,
			<6321 5879 5487 5207 5127 5106>,
			<6358 5909 5504 5210 5122 5103>,
			<6398 5940 5521 5212 5120 5102>,
			<6439 5971 5541 5215 5123 5106>,
			<6483 6006 5561 5217 5124 5107>,
			<6534 6048 5582 5219 5123 5106>,
			<6582 6093 5601 5220 5119 5101>,
			<6543 6065 5580 5211 5113 5095>,
			<6614 6143 5627 5224 5121 5106>,
			<6664 6186 5661 5235 5130 5115>,
			<6712 6234 5696 5249 5139 5124>,
			<6769 6279 5727 5265 5152 5134>,
			<6817 6328 5760 5272 5151 5131>,
			<6872 6362 5777 5262 5130 5110>,
			<6939 6413 5806 5266 5133 5112>,
			<7092 6501 5899 5294 5140 5121>,
			<7614 6612 6018 5331 5160 5141>,
			<7614 6612 6018 5331 5160 5141>,
			<7614 6612 6018 5331 5160 5141>;
	};

};
